AUTOSAR XML (schema 00046)
package /ComponentTypes
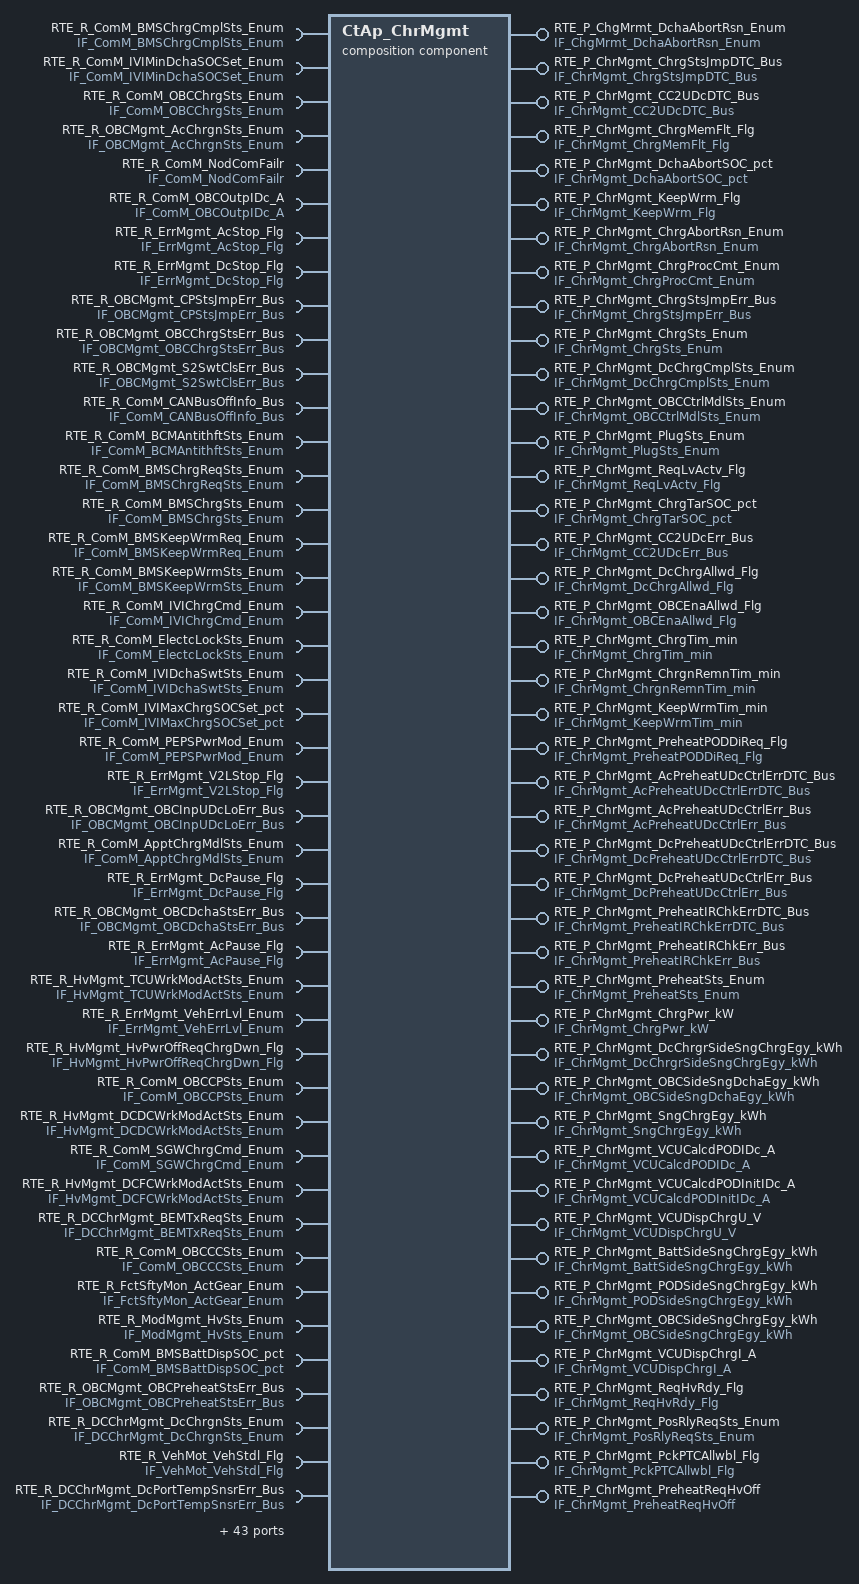
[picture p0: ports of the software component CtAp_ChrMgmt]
  composition sw component type CtAp_ChrMgmt
    4 x require port:
      RTE_R_ComM_BMSChrgCmplSts_Enum: nonqueued-receiver-com-spec{data-element=tec_ComM_BMSChrgCmplSts_Enum, filter=data-filter-type=ALWAYS, init-value=0}, required-interface=IF_ComM_BMSChrgCmplSts_Enum
      RTE_R_ComM_IVIMinDchaSOCSet_Enum: nonqueued-receiver-com-spec{data-element=tec_ComM_IVIMinDchaSOCSet_Enum, filter=data-filter-type=ALWAYS, init-value=0}, required-interface=IF_ComM_IVIMinDchaSOCSet_Enum
      RTE_R_ComM_OBCChrgSts_Enum: nonqueued-receiver-com-spec{data-element=tec_ComM_OBCChrgSts_Enum, filter=data-filter-type=ALWAYS, init-value=0}, required-interface=IF_ComM_OBCChrgSts_Enum
      RTE_R_OBCMgmt_AcChrgnSts_Enum: nonqueued-receiver-com-spec{data-element=tec_OBCMgmt_AcChrgnSts_Enum, filter=data-filter-type=ALWAYS, init-value=0}, required-interface=IF_OBCMgmt_AcChrgnSts_Enum
    40 x provide port:
      RTE_P_ChgMrmt_DchaAbortRsn_Enum: nonqueued-sender-com-spec{data-element=tec_ChrMgmt_DchaAbortRsn_Enum, init-value=0}, provided-interface=IF_ChgMrmt_DchaAbortRsn_Enum
      RTE_P_ChrMgmt_ChrgStsJmpDTC_Bus: nonqueued-sender-com-spec{data-element=tec_ChrMgmt_ChrgStsJmpErrDTC_Bus, init-value=fields=[ChrMgmt_MonStatChrgStsJmpErrDTC:0, ChrMgmt_MonResChrgStsJmpErrDTC:0, ChrMgmt_ErrStatChrgStsJmpErrDTC:0, ChrMgmt_ErrResChrgStsJmpErrDTC:0]}, provided-interface=IF_ChrMgmt_ChrgStsJmpDTC_Bus
      RTE_P_ChrMgmt_CC2UDcDTC_Bus: nonqueued-sender-com-spec{data-element=tec_ChrMgmt_CC2UDcErrDTC_Bus, init-value=fields=[ChrMgmt_MonStatCC2UDcErrDTC:0, ChrMgmt_MonResCC2UDcErrDTC:0, ChrMgmt_ErrStatCC2UDcErrDTC:0, ChrMgmt_ErrResCC2UDcErrDTC:0]}, provided-interface=IF_ChrMgmt_CC2UDcDTC_Bus
      RTE_P_ChrMgmt_ChrgMemFlt_Flg: nonqueued-sender-com-spec{data-element=tec_ChrMgmt_ChrgMemFlt_Flg, init-value=0}, provided-interface=IF_ChrMgmt_ChrgMemFlt_Flg
      RTE_P_ChrMgmt_DchaAbortSOC_pct: nonqueued-sender-com-spec{data-element=tec_ChrMgmt_DchaAbortSOC_pct, init-value=0}, provided-interface=IF_ChrMgmt_DchaAbortSOC_pct
      RTE_P_ChrMgmt_KeepWrm_Flg: nonqueued-sender-com-spec{data-element=tec_ChrMgmt_KeepWrm_Flg, init-value=0}, provided-interface=IF_ChrMgmt_KeepWrm_Flg
      RTE_P_ChrMgmt_ChrgAbortRsn_Enum: nonqueued-sender-com-spec{data-element=tec_ChrMgmt_ChrgAbortRsn_Enum, init-value=0}, provided-interface=IF_ChrMgmt_ChrgAbortRsn_Enum
      RTE_P_ChrMgmt_ChrgProcCmt_Enum: nonqueued-sender-com-spec{data-element=tec_ChrMgmt_ChrgProcCmt_Enum, init-value=0}, provided-interface=IF_ChrMgmt_ChrgProcCmt_Enum
      RTE_P_ChrMgmt_ChrgStsJmpErr_Bus: nonqueued-sender-com-spec{data-element=tec_ChrMgmt_ChrgStsJmpErr_Bus, init-value=fields=[ChrMgmt_MonStatChrgStsJmpErr:0, ChrMgmt_MonResChrgStsJmpErr:0, ChrMgmt_ErrStatChrgStsJmpErr:0, ChrMgmt_ErrResChrgStsJmpErr:0]}, provided-interface=IF_ChrMgmt_ChrgStsJmpErr_Bus
      RTE_P_ChrMgmt_ChrgSts_Enum: nonqueued-sender-com-spec{data-element=tec_ChrMgmt_ChrgSts_Enum, init-value=0}, provided-interface=IF_ChrMgmt_ChrgSts_Enum
      RTE_P_ChrMgmt_DcChrgCmplSts_Enum: nonqueued-sender-com-spec{data-element=tec_ChrMgmt_DcChrgCmplSts_Enum, init-value=0}, provided-interface=IF_ChrMgmt_DcChrgCmplSts_Enum
      RTE_P_ChrMgmt_OBCCtrlMdlSts_Enum: nonqueued-sender-com-spec{data-element=tec_ChrMgmt_OBCCtrlMdlSts_Enum, init-value=0}, provided-interface=IF_ChrMgmt_OBCCtrlMdlSts_Enum
      RTE_P_ChrMgmt_PlugSts_Enum: nonqueued-sender-com-spec{data-element=tec_ChrMgmt_PlugSts_Enum, init-value=0}, provided-interface=IF_ChrMgmt_PlugSts_Enum
      RTE_P_ChrMgmt_ReqLvActv_Flg: nonqueued-sender-com-spec{data-element=tec_ChrMgmt_ReqLvActv_Flg, init-value=0}, provided-interface=IF_ChrMgmt_ReqLvActv_Flg
      RTE_P_ChrMgmt_ChrgTarSOC_pct: nonqueued-sender-com-spec{data-element=tec_ChrMgmt_ChrgTarSOC_pct, init-value=0}, provided-interface=IF_ChrMgmt_ChrgTarSOC_pct
      RTE_P_ChrMgmt_CC2UDcErr_Bus: nonqueued-sender-com-spec{data-element=tec_ChrMgmt_CC2UDcErr_Bus, init-value=fields=[ChrMgmt_MonStatCC2UDcErr:0, ChrMgmt_MonResCC2UDcErr:0, ChrMgmt_ErrStatCC2UDcErr:0, ChrMgmt_ErrResCC2UDcErr:0]}, provided-interface=IF_ChrMgmt_CC2UDcErr_Bus
      RTE_P_ChrMgmt_DcChrgAllwd_Flg: nonqueued-sender-com-spec{data-element=tec_ChrMgmt_DcChrgAllwd_Flg, init-value=0}, provided-interface=IF_ChrMgmt_DcChrgAllwd_Flg
      RTE_P_ChrMgmt_OBCEnaAllwd_Flg: nonqueued-sender-com-spec{data-element=tec_ChrMgmt_OBCEnaAllwd_Flg, init-value=0}, provided-interface=IF_ChrMgmt_OBCEnaAllwd_Flg
      RTE_P_ChrMgmt_ChrgTim_min: nonqueued-sender-com-spec{data-element=tec_ChrMgmt_ChrgTim_min, init-value=0}, provided-interface=IF_ChrMgmt_ChrgTim_min
      RTE_P_ChrMgmt_ChrgnRemnTim_min: nonqueued-sender-com-spec{data-element=tec_ChrgMgmt_ChrgnRemnTim_min, init-value=0}, provided-interface=IF_ChrMgmt_ChrgnRemnTim_min
      RTE_P_ChrMgmt_KeepWrmTim_min: nonqueued-sender-com-spec{data-element=tec_ChrMgmt_KeepWrmTim_min, init-value=0}, provided-interface=IF_ChrMgmt_KeepWrmTim_min
      RTE_P_ChrMgmt_PreheatPODDiReq_Flg: nonqueued-sender-com-spec{data-element=tec_ChrMgmt_PreheatPODDiReq_Flg, init-value=0}, provided-interface=IF_ChrMgmt_PreheatPODDiReq_Flg
      RTE_P_ChrMgmt_AcPreheatUDcCtrlErrDTC_Bus: nonqueued-sender-com-spec{data-element=tec_ChrMgmt_AcPreheatUDcCtrlErrDTC_Bus, init-value=fields=[ChrMgmt_MonStatAcPreheatUDcCtrlErrDTC:0, ChrMgmt_MonResAcPreheatUDcCtrlErrDTC:0, ChrMgmt_ErrStatAcPreheatUDcCtrlErrDTC:0, ChrMgmt_ErrResAcPreheatUDcCtrlErrDTC:0]}, provided-interface=IF_ChrMgmt_AcPreheatUDcCtrlErrDTC_Bus
      RTE_P_ChrMgmt_AcPreheatUDcCtrlErr_Bus: nonqueued-sender-com-spec{data-element=tec_ChrMgmt_AcPreheatUDcCtrlErr_Bus, init-value=fields=[ChrMgmt_MonStatAcPreheatUDcCtrlErr:0, ChrMgmt_MonResAcPreheatUDcCtrlErr:0, ChrMgmt_ErrStatAcPreheatUDcCtrlErr:0, ChrMgmt_ErrResAcPreheatUDcCtrlErr:0]}, provided-interface=IF_ChrMgmt_AcPreheatUDcCtrlErr_Bus
      RTE_P_ChrMgmt_DcPreheatUDcCtrlErrDTC_Bus: nonqueued-sender-com-spec{data-element=tec_ChrMgmt_DcPreheatUDcCtrlErrDTC_Bus, init-value=fields=[ChrMgmt_MonStatDcPreheatUDcCtrlErrDTC:0, ChrMgmt_MonResDcPreheatUDcCtrlErrDTC:0, ChrMgmt_ErrStatDcPreheatUDcCtrlErrDTC:0, ChrMgmt_ErrResDcPreheatUDcCtrlErrDTC:0]}, provided-interface=IF_ChrMgmt_DcPreheatUDcCtrlErrDTC_Bus
      RTE_P_ChrMgmt_DcPreheatUDcCtrlErr_Bus: nonqueued-sender-com-spec{data-element=tec_ChrMgmt_DcPreheatUDcCtrlErr_Bus, init-value=fields=[ChrMgmt_MonStatDcPreheatUDcCtrlErr:0, ChrMgmt_MonResDcPreheatUDcCtrlErr:0, ChrMgmt_ErrStatDcPreheatUDcCtrlErr:0, ChrMgmt_ErrResDcPreheatUDcCtrlErr:0]}, provided-interface=IF_ChrMgmt_DcPreheatUDcCtrlErr_Bus
      RTE_P_ChrMgmt_PreheatIRChkErrDTC_Bus: nonqueued-sender-com-spec{data-element=tec_ChrMgmt_PreheatIRChkErrDTC_Bus, init-value=fields=[ChrMgmt_MonStatPreheatIRChkErrDTC:0, ChrMgmt_MonResPreheatIRChkErrDTC:0, ChrMgmt_ErrStatPreheatIRChkErrDTC:0, ChrMgmt_ErrResPreheatIRChkErrDTC:0]}, provided-interface=IF_ChrMgmt_PreheatIRChkErrDTC_Bus
      RTE_P_ChrMgmt_PreheatIRChkErr_Bus: nonqueued-sender-com-spec{data-element=tec_ChrMgmt_PreheatIRChkErr_Bus, init-value=fields=[ChrMgmt_MonStatPreheatIRChkErr:0, ChrMgmt_MonResPreheatIRChkErr:0, ChrMgmt_ErrStatPreheatIRChkErr:0, ChrMgmt_ErrResPreheatIRChkErr:0]}, provided-interface=IF_ChrMgmt_PreheatIRChkErr_Bus
      RTE_P_ChrMgmt_PreheatSts_Enum: nonqueued-sender-com-spec{data-element=tec_ChrMgmt_PreheatSts_Enum, init-value=0}, provided-interface=IF_ChrMgmt_PreheatSts_Enum
      RTE_P_ChrMgmt_ChrgPwr_kW: nonqueued-sender-com-spec{data-element=tec_ChrMgmt_VCUDispChrgPwr_kW, init-value=0}, provided-interface=IF_ChrMgmt_ChrgPwr_kW
      RTE_P_ChrMgmt_DcChrgrSideSngChrgEgy_kWh: nonqueued-sender-com-spec{data-element=tec_ChrMgmt_DcChrgrSideSngChrgEgy_kWh, init-value=0}, provided-interface=IF_ChrMgmt_DcChrgrSideSngChrgEgy_kWh
      RTE_P_ChrMgmt_OBCSideSngDchaEgy_kWh: nonqueued-sender-com-spec{data-element=tec_ChrMgmt_OBCSideSngDchaEgy_kWh, init-value=0}, provided-interface=IF_ChrMgmt_OBCSideSngDchaEgy_kWh
      RTE_P_ChrMgmt_SngChrgEgy_kWh: nonqueued-sender-com-spec{data-element=tec_ChrMgmt_SngChrgEgy_kWh, init-value=0}, provided-interface=IF_ChrMgmt_SngChrgEgy_kWh
      RTE_P_ChrMgmt_VCUCalcdPODIDc_A: nonqueued-sender-com-spec{data-element=tec_ChrMgmt_VCUCalcdPODIDc_A, init-value=0}, provided-interface=IF_ChrMgmt_VCUCalcdPODIDc_A
      RTE_P_ChrMgmt_VCUCalcdPODInitIDc_A: nonqueued-sender-com-spec{data-element=tec_ChrMgmt_VCUCalcdPODInitIDc_A, init-value=0}, provided-interface=IF_ChrMgmt_VCUCalcdPODInitIDc_A
      RTE_P_ChrMgmt_VCUDispChrgU_V: nonqueued-sender-com-spec{data-element=tec_ChrMgmt_VCUDispChrgU_V, init-value=0}, provided-interface=IF_ChrMgmt_VCUDispChrgU_V
      RTE_P_ChrMgmt_BattSideSngChrgEgy_kWh: nonqueued-sender-com-spec{data-element=tec_ChrMgmt_BattSideSngChrgEgy_kWh, init-value=0}, provided-interface=IF_ChrMgmt_BattSideSngChrgEgy_kWh
      RTE_P_ChrMgmt_PODSideSngChrgEgy_kWh: nonqueued-sender-com-spec{data-element=tec_ChrMgmt_PODSideSngChrgEgy_kWh, init-value=0}, provided-interface=IF_ChrMgmt_PODSideSngChrgEgy_kWh
      RTE_P_ChrMgmt_OBCSideSngChrgEgy_kWh: nonqueued-sender-com-spec{data-element=tec_ChrMgmt_OBCSideSngChrgEgy_kWh, init-value=0}, provided-interface=IF_ChrMgmt_OBCSideSngChrgEgy_kWh
      RTE_P_ChrMgmt_VCUDispChrgI_A: nonqueued-sender-com-spec{data-element=tec_ChrMgmt_VCUDispChrgI_A, init-value=0}, provided-interface=IF_ChrMgmt_VCUDispChrgI_A
    44 x require port:
      RTE_R_ComM_NodComFailr: required-interface=IF_ComM_NodComFailr
        required-com-specs:
          data-element=tec_ComM_ACUNodComFailr_Flg, filter=data-filter-type=ALWAYS, init-value=0
          data-element=tec_ComM_SGWNodComFailr_Flg, filter=data-filter-type=ALWAYS, init-value=0
          data-element=tec_ComM_CGWNodComFailr_Flg, filter=data-filter-type=ALWAYS, init-value=0
          data-element=tec_ComM_TCUNodComFailr_Flg, filter=data-filter-type=ALWAYS, init-value=0
          data-element=tec_ComM_BCMNodComFailr_Flg, filter=data-filter-type=ALWAYS, init-value=0
          data-element=tec_ComM_PRNDNodComFailr_Flg, filter=data-filter-type=ALWAYS, init-value=0
          data-element=tec_ComM_IVINodComFailr_Flg, filter=data-filter-type=ALWAYS, init-value=0
          data-element=tec_ComM_DCDCNodComFailr_Flg, filter=data-filter-type=ALWAYS, init-value=0
          data-element=tec_ComM_OBCNodComFailr_Flg, filter=data-filter-type=ALWAYS, init-value=0
          data-element=tec_ComM_CHIBSNodComFailr_Flg, filter=data-filter-type=ALWAYS, init-value=0
          data-element=tec_ComM_MCUNodComFailr_Flg, filter=data-filter-type=ALWAYS, init-value=0
          data-element=tec_ComM_EVCOMNodComFailr_Flg, filter=data-filter-type=ALWAYS, init-value=0
          data-element=tec_ComM_EPTIBSNodComFailr_Flg, filter=data-filter-type=ALWAYS, init-value=0
          data-element=tec_ComM_DCMNodComFailr_Flg, filter=data-filter-type=ALWAYS, init-value=0
          data-element=tec_ComM_BMSNodComFailr_Flg, filter=data-filter-type=ALWAYS, init-value=0
          data-element=tec_ComM_APTCNodComFailr_Flg, filter=data-filter-type=ALWAYS, init-value=0
          data-element=tec_ComM_ADCUNodComFailr_Flg, filter=data-filter-type=ALWAYS, init-value=0
          data-element=tec_ComM_DCMRRNodComFailr_Flg, filter=data-filter-type=ALWAYS, init-value=0
          data-element=tec_ComM_DCMRLNodComFailr_Flg, filter=data-filter-type=ALWAYS, init-value=0
          data-element=tec_ComM_DCMFRNodComFailr_Flg, filter=data-filter-type=ALWAYS, init-value=0
          data-element=tec_ComM_DCMFLNodComFailr_Flg, filter=data-filter-type=ALWAYS, init-value=0
          data-element=tec_ComM_SGWCHNodComFailr_Flg, filter=data-filter-type=ALWAYS, init-value=0
      RTE_R_ComM_OBCOutpIDc_A: nonqueued-receiver-com-spec{data-element=tec_ComM_OBCOutpIDc_A, filter=data-filter-type=ALWAYS, init-value=0}, required-interface=IF_ComM_OBCOutpIDc_A
      RTE_R_ErrMgmt_AcStop_Flg: nonqueued-receiver-com-spec{data-element=tec_ErrMgmt_AcStop_Flg, filter=data-filter-type=ALWAYS, init-value=0}, required-interface=IF_ErrMgmt_AcStop_Flg
      RTE_R_ErrMgmt_DcStop_Flg: nonqueued-receiver-com-spec{data-element=tec_ErrMgmt_DcStop_Flg, filter=data-filter-type=ALWAYS, init-value=0}, required-interface=IF_ErrMgmt_DcStop_Flg
      RTE_R_OBCMgmt_CPStsJmpErr_Bus: nonqueued-receiver-com-spec{data-element=tec_OBCMgmt_CPStsJmpErr_Bus, filter=data-filter-type=ALWAYS, init-value=fields=[OBCMgmt_MonStatCPStsJmpErr:0, OBCMgmt_MonResCPStsJmpErr:0, OBCMgmt_ErrStatCPStsJmpErr:0, OBCMgmt_ErrResCPStsJmpErr:0]}, required-interface=IF_OBCMgmt_CPStsJmpErr_Bus
      RTE_R_OBCMgmt_OBCChrgStsErr_Bus: nonqueued-receiver-com-spec{data-element=tec_OBCMgmt_OBCChrgStsErr_Bus, filter=data-filter-type=ALWAYS, init-value=fields=[OBCMgmt_MonStatOBCChrgStsErr:0, OBCMgmt_MonResOBCChrgStsErr:0, OBCMgmt_ErrStatOBCChrgStsErr:0, OBCMgmt_ErrResOBCChrgStsErr:0]}, required-interface=IF_OBCMgmt_OBCChrgStsErr_Bus
      RTE_R_OBCMgmt_S2SwtClsErr_Bus: nonqueued-receiver-com-spec{data-element=tec_OBCMgmt_S2SwtClsErr_Bus, filter=data-filter-type=ALWAYS, init-value=fields=[OBCMgmt_MonStatS2SwtClsErr:0, OBCMgmt_MonResS2SwtClsErr:0, OBCMgmt_ErrStatS2SwtClsErr:0, OBCMgmt_ErrResS2SwtClsErr:0]}, required-interface=IF_OBCMgmt_S2SwtClsErr_Bus
      RTE_R_ComM_CANBusOffInfo_Bus: required-interface=IF_ComM_CANBusOffInfo_Bus
        required-com-specs:
          data-element=tec_ComM_EPTCANBusOffInfo_Bus, filter=data-filter-type=ALWAYS, init-value=fields=[ComM_MonStatEPTCANBusOffInfo:0, ComM_MonResEPTCANBusOffInfo:0, ComM_ErrStatEPTCANBusOffInfo:0, ComM_ErrResEPTCANBusOffInfo:0]
          data-element=tec_ComM_CHCANBusOffInfo_Bus, filter=data-filter-type=ALWAYS, init-value=fields=[ComM_MonStatCHCANBusOffInfo:0, ComM_MonResCHCANBusOffInfo:0, ComM_ErrStatCHCANBusOffInfo:0, ComM_ErrResCHCANBusOffInfo:0]
          data-element=tec_ComM_EPTCANBusOffDTCInfo_Bus, filter=data-filter-type=ALWAYS, init-value=fields=[ComM_MonStatEPTCANBusOffDTCInfo:0, ComM_MonResEPTCANBusOffDTCInfo:0, ComM_ErrStatEPTCANBusOffDTCInfo:0, ComM_ErrResEPTCANBusOffDTCInfo:0]
          data-element=tec_ComM_CHCANBusOffDTCInfo_Bus, filter=data-filter-type=ALWAYS, init-value=fields=[ComM_MonStatCHCANBusOffDTCInfo:0, ComM_MonResCHCANBusOffDTCInfo:0, ComM_ErrStatCHCANBusOffDTCInfo:0, ComM_ErrResCHCANBusOffDTCInfo:0]
      RTE_R_ComM_BCMAntithftSts_Enum: nonqueued-receiver-com-spec{data-element=tec_ComM_BCMAntithftSts_Enum, filter=data-filter-type=ALWAYS, init-value=0}, required-interface=IF_ComM_BCMAntithftSts_Enum
      RTE_R_ComM_BMSChrgReqSts_Enum: nonqueued-receiver-com-spec{data-element=tec_ComM_BMSChrgReqSts_Enum, filter=data-filter-type=ALWAYS, init-value=0}, required-interface=IF_ComM_BMSChrgReqSts_Enum
      RTE_R_ComM_BMSChrgSts_Enum: nonqueued-receiver-com-spec{data-element=tec_ComM_BMSChrgSts_Enum, filter=data-filter-type=ALWAYS, init-value=0}, required-interface=IF_ComM_BMSChrgSts_Enum
      RTE_R_ComM_BMSKeepWrmReq_Enum: nonqueued-receiver-com-spec{data-element=tec_ComM_BMSKeepWrmReq_Enum, filter=data-filter-type=ALWAYS, init-value=0}, required-interface=IF_ComM_BMSKeepWrmReq_Enum
      RTE_R_ComM_BMSKeepWrmSts_Enum: nonqueued-receiver-com-spec{data-element=tec_ComM_BMSKeepWrmSts_Enum, filter=data-filter-type=ALWAYS, init-value=0}, required-interface=IF_ComM_BMSKeepWrmSts_Enum
      RTE_R_ComM_IVIChrgCmd_Enum: nonqueued-receiver-com-spec{data-element=tec_ComM_IVIChrgCmd_Enum, filter=data-filter-type=ALWAYS, init-value=0}, required-interface=IF_ComM_IVIChrgCmd_Enum
      RTE_R_ComM_ElectcLockSts_Enum: nonqueued-receiver-com-spec{data-element=tec_ComM_ElectcLockSts_Enum, filter=data-filter-type=ALWAYS, init-value=0}, required-interface=IF_ComM_ElectcLockSts_Enum
      RTE_R_ComM_IVIDchaSwtSts_Enum: nonqueued-receiver-com-spec{data-element=tec_ComM_IVIDchaSwtSts_Enum, filter=data-filter-type=ALWAYS, init-value=0}, required-interface=IF_ComM_IVIDchaSwtSts_Enum
      RTE_R_ComM_IVIMaxChrgSOCSet_pct: nonqueued-receiver-com-spec{data-element=tec_ComM_IVIMaxChrgSOCSet_pct, filter=data-filter-type=ALWAYS, init-value=0}, required-interface=IF_ComM_IVIMaxChrgSOCSet_pct
      RTE_R_ComM_PEPSPwrMod_Enum: nonqueued-receiver-com-spec{data-element=tec_ComM_PEPSPwrMod_Enum, filter=data-filter-type=ALWAYS, init-value=0}, required-interface=IF_ComM_PEPSPwrMod_Enum
      RTE_R_ErrMgmt_V2LStop_Flg: nonqueued-receiver-com-spec{data-element=tec_ErrMgmt_V2LStop_Flg, filter=data-filter-type=ALWAYS, init-value=0}, required-interface=IF_ErrMgmt_V2LStop_Flg
      RTE_R_OBCMgmt_OBCInpUDcLoErr_Bus: nonqueued-receiver-com-spec{data-element=tec_OBCMgmt_OBCInpUDcLoErr_Bus, filter=data-filter-type=ALWAYS, init-value=fields=[OBCMgmt_MonStatOBCInpUDcLoErr:0, OBCMgmt_MonResOBCInpUDcLoErr:0, OBCMgmt_ErrStatOBCInpUDcLoErr:0, OBCMgmt_ErrResOBCInpUDcLoErr:0]}, required-interface=IF_OBCMgmt_OBCInpUDcLoErr_Bus
      RTE_R_ComM_ApptChrgMdlSts_Enum: nonqueued-receiver-com-spec{data-element=tec_ComM_ApptChrgMdlSts_Enum, filter=data-filter-type=ALWAYS, init-value=0}, required-interface=IF_ComM_ApptChrgMdlSts_Enum
      RTE_R_ErrMgmt_DcPause_Flg: nonqueued-receiver-com-spec{data-element=tec_ErrMgmt_DcPause_Flg, filter=data-filter-type=ALWAYS, init-value=0}, required-interface=IF_ErrMgmt_DcPause_Flg
      RTE_R_OBCMgmt_OBCDchaStsErr_Bus: nonqueued-receiver-com-spec{data-element=tec_OBCMgmt_OBCDchaStsErr_Bus, filter=data-filter-type=ALWAYS, init-value=fields=[OBCMgmt_MonStatOBCDchaStsErr:0, OBCMgmt_MonResOBCDchaStsErr:0, OBCMgmt_ErrStatOBCDchaStsErr:0, OBCMgmt_ErrResOBCDchaStsErr:0]}, required-interface=IF_OBCMgmt_OBCDchaStsErr_Bus
      RTE_R_ErrMgmt_AcPause_Flg: nonqueued-receiver-com-spec{data-element=tec_ErrMgmt_AcPause_Flg, filter=data-filter-type=ALWAYS, init-value=0}, required-interface=IF_ErrMgmt_AcPause_Flg
      RTE_R_HvMgmt_TCUWrkModActSts_Enum: nonqueued-receiver-com-spec{data-element=tec_HvMgmt_TCUWrkModActSts_Enum, filter=data-filter-type=ALWAYS, init-value=0}, required-interface=IF_HvMgmt_TCUWrkModActSts_Enum
      RTE_R_ErrMgmt_VehErrLvl_Enum: nonqueued-receiver-com-spec{data-element=tec_ErrMgmt_VehErrLvl_Enum, filter=data-filter-type=ALWAYS, init-value=0}, required-interface=IF_ErrMgmt_VehErrLvl_Enum
      RTE_R_HvMgmt_HvPwrOffReqChrgDwn_Flg: nonqueued-receiver-com-spec{data-element=tec_HvMgmt_HvPwrOffReqChrgDwn_Flg, filter=data-filter-type=ALWAYS, init-value=0}, required-interface=IF_HvMgmt_HvPwrOffReqChrgDwn_Flg
      RTE_R_ComM_OBCCPSts_Enum: nonqueued-receiver-com-spec{data-element=tec_ComM_OBCCPSts_Enum, filter=data-filter-type=ALWAYS, init-value=0}, required-interface=IF_ComM_OBCCPSts_Enum
      RTE_R_HvMgmt_DCDCWrkModActSts_Enum: nonqueued-receiver-com-spec{data-element=tec_HvMgmt_DCDCWrkModActSts_Enum, filter=data-filter-type=ALWAYS, init-value=0}, required-interface=IF_HvMgmt_DCDCWrkModActSts_Enum
      RTE_R_ComM_SGWChrgCmd_Enum: nonqueued-receiver-com-spec{data-element=tec_ComM_SGWChrgCmd_Enum, filter=data-filter-type=ALWAYS, init-value=0}, required-interface=IF_ComM_SGWChrgCmd_Enum
      RTE_R_HvMgmt_DCFCWrkModActSts_Enum: nonqueued-receiver-com-spec{data-element=tec_HvMgmt_DCFCWrkModActSts_Enum, filter=data-filter-type=ALWAYS, init-value=0}, required-interface=IF_HvMgmt_DCFCWrkModActSts_Enum
      RTE_R_DCChrMgmt_BEMTxReqSts_Enum: nonqueued-receiver-com-spec{data-element=tec_DCChrMgmt_BEMTxReqSts_Enum, filter=data-filter-type=ALWAYS, init-value=0}, required-interface=IF_DCChrMgmt_BEMTxReqSts_Enum
      RTE_R_ComM_OBCCCSts_Enum: nonqueued-receiver-com-spec{data-element=tec_ComM_OBCCCSts_Enum, filter=data-filter-type=ALWAYS, init-value=0}, required-interface=IF_ComM_OBCCCSts_Enum
      RTE_R_FctSftyMon_ActGear_Enum: nonqueued-receiver-com-spec{data-element=tec_FctSftyMon_ActGear_Enum, filter=data-filter-type=ALWAYS, init-value=0}, required-interface=IF_FctSftyMon_ActGear_Enum
      RTE_R_ModMgmt_HvSts_Enum: nonqueued-receiver-com-spec{data-element=tec_ModMgmt_HvSts_Enum, filter=data-filter-type=ALWAYS, init-value=0}, required-interface=IF_ModMgmt_HvSts_Enum
      RTE_R_ComM_BMSBattDispSOC_pct: nonqueued-receiver-com-spec{data-element=tec_ComM_BMSBattDispSOC_pct, filter=data-filter-type=ALWAYS, init-value=0}, required-interface=IF_ComM_BMSBattDispSOC_pct
      RTE_R_OBCMgmt_OBCPreheatStsErr_Bus: nonqueued-receiver-com-spec{data-element=tec_OBCMgmt_OBCPreheatStsErr_Bus, filter=data-filter-type=ALWAYS, init-value=fields=[OBCMgmt_MonStatOBCPreheatStsErr:0, OBCMgmt_MonResOBCPreheatStsErr:0, OBCMgmt_ErrStatOBCPreheatStsErr:0, OBCMgmt_ErrResOBCPreheatStsErr:0]}, required-interface=IF_OBCMgmt_OBCPreheatStsErr_Bus
      RTE_R_DCChrMgmt_DcChrgnSts_Enum: nonqueued-receiver-com-spec{data-element=tec_DCChrMgmt_DcChrgnSts_Enum, filter=data-filter-type=ALWAYS, init-value=0}, required-interface=IF_DCChrMgmt_DcChrgnSts_Enum
      RTE_R_VehMot_VehStdl_Flg: nonqueued-receiver-com-spec{data-element=tec_VehMot_VehStdl_Flg, filter=data-filter-type=ALWAYS, init-value=0}, required-interface=IF_VehMot_VehStdl_Flg
      RTE_R_DCChrMgmt_DcPortTempSnsrErr_Bus: nonqueued-receiver-com-spec{data-element=tec_DCChrMgmt_DcPortTempSnsrErr_Bus, filter=data-filter-type=ALWAYS, init-value=fields=[DCChrMgmt_MonStatDcPortTempSnsrErr:0, DCChrMgmt_MonResDcPortTempSnsrErr:0, DCChrMgmt_ErrStatDcPortTempSnsrErr:0, DCChrMgmt_ErrResDcPortTempSnsrErr:0]}, required-interface=IF_DCChrMgmt_DcPortTempSnsrErr_Bus
      RTE_R_DCChrMgmt_IRMeasEnaErr_Bus: nonqueued-receiver-com-spec{data-element=tec_DCChrMgmt_IRMeasEnaErr_Bus, filter=data-filter-type=ALWAYS, init-value=fields=[DCChrMgmt_MonStatIRMeasEnaErr:0, DCChrMgmt_MonResIRMeasEnaErr:0, DCChrMgmt_ErrStatIRMeasEnaErr:0, DCChrMgmt_ErrResIRMeasEnaErr:0]}, required-interface=IF_DCChrMgmt_IRMeasEnaErr_Bus
      RTE_R_OBCMgmt_OBCDiErr_Bus: nonqueued-receiver-com-spec{data-element=tec_OBCMgmt_OBCDiErr_Bus, filter=data-filter-type=ALWAYS, init-value=fields=[OBCMgmt_MonStatOBCDiErr:0, OBCMgmt_MonResOBCDiErr:0, OBCMgmt_ErrStatOBCDiErr:0, OBCMgmt_ErrResOBCDiErr:0]}, required-interface=IF_OBCMgmt_OBCDiErr_Bus
      RTE_R_LvMgmt_BSBattUDcNorm_Flg: nonqueued-receiver-com-spec{data-element=tec_LvMgmt_BSBattUDcNorm_Flg, filter=data-filter-type=ALWAYS, init-value=0}, required-interface=IF_LvMgmt_BSBattUDcNorm_Flg
      RTE_R_DCChrMgmt_DcPortTempErrLvl2_Bus: nonqueued-receiver-com-spec{data-element=tec_DCChrMgmt_DcPortTempErrLvl2_Bus, filter=data-filter-type=ALWAYS, init-value=fields=[DCChrMgmt_MonStatDcPortTempErrLvl2:0, DCChrMgmt_MonResDcPortTempErrLvl2:0, DCChrMgmt_ErrStatDcPortTempErrLvl2:0, DCChrMgmt_ErrResDcPortTempErrLvl2:0]}, required-interface=IF_DCChrMgmt_DcPortTempErrLvl2_Bus
    provide port RTE_P_ChrMgmt_ReqHvRdy_Flg: nonqueued-sender-com-spec{data-element=tec_ChrMgmt_ReqHvRdy_Flg, init-value=0}, provided-interface=IF_ChrMgmt_ReqHvRdy_Flg
    28 x require port:
      RTE_R_HvMgmt_BMSPosRlyActSts_Enum: nonqueued-receiver-com-spec{data-element=tec_HvMgmt_BMSPosRlyActSts_Enum, filter=data-filter-type=ALWAYS, init-value=0}, required-interface=IF_HvMgmt_BMSPosRlyActSts_Enum
      RTE_R_IOAbs_CC2SigUDc_mV: nonqueued-receiver-com-spec{data-element=tec_IOAbs_CC2SigUDc_mV, filter=data-filter-type=ALWAYS, init-value=0}, required-interface=IF_IOAbs_CC2SigUDc_mV
      RTE_R_DCChrMgmt_IRMeasDiErr_Bus: nonqueued-receiver-com-spec{data-element=tec_DCChrMgmt_IRMeasDiErr_Bus, filter=data-filter-type=ALWAYS, init-value=fields=[DCChrMgmt_MonStatIRMeasDiErr:0, DCChrMgmt_MonResIRMeasDiErr:0, DCChrMgmt_ErrStatIRMeasDiErr:0, DCChrMgmt_ErrResIRMeasDiErr:0]}, required-interface=IF_DCChrMgmt_IRMeasDiErr_Bus
      RTE_R_ComM_BMSRemnChrgTim_min: nonqueued-receiver-com-spec{data-element=tec_ComM_BMSRemnChrgTim_min, filter=data-filter-type=ALWAYS, init-value=0}, required-interface=IF_ComM_BMSRemnChrgTim_min
      RTE_R_ComM_BattMinTemp_C: nonqueued-receiver-com-spec{data-element=tec_ComM_BMSBattMinTemp_C, filter=data-filter-type=ALWAYS, init-value=0}, required-interface=IF_ComM_BattMinTemp_C
      RTE_R_ComM_CMLMaxOutpIDc_A: nonqueued-receiver-com-spec{data-element=tec_ComM_CMLMaxOutpIDc_A, filter=data-filter-type=ALWAYS, init-value=0}, required-interface=IF_ComM_CMLMaxOutpIDc_A
      RTE_R_ChrMgmt_ChrgSts_Enum: nonqueued-receiver-com-spec{data-element=tec_ChrMgmt_ChrgSts_Enum, filter=data-filter-type=ALWAYS, init-value=0}, required-interface=IF_ChrMgmt_ChrgSts_Enum
      RTE_R_ChrMgmt_ChrgTarSOC_pct: nonqueued-receiver-com-spec{data-element=tec_ChrMgmt_ChrgTarSOC_pct, filter=data-filter-type=ALWAYS, init-value=0}, required-interface=IF_ChrMgmt_ChrgTarSOC_pct
      RTE_R_ComM_BMSBattRateCp_Ah: nonqueued-receiver-com-spec{data-element=tec_ComM_BMSBattRateCp_Ah, filter=data-filter-type=ALWAYS, init-value=0}, required-interface=IF_ComM_BMSBattRateCp_Ah
      RTE_R_DCChrMgmt_DcChrgnMod_Enum: nonqueued-receiver-com-spec{data-element=tec_DCChrMgmt_DcChrgnMod_Enum, filter=data-filter-type=ALWAYS, init-value=0}, required-interface=IF_DCChrMgmt_DcChrgnMod_Enum
      RTE_R_ComM_BattMaxTemp_C: nonqueued-receiver-com-spec{data-element=tec_ComM_BMSBattMaxTemp_C, filter=data-filter-type=ALWAYS, init-value=0}, required-interface=IF_ComM_BattMaxTemp_C
      RTE_R_OBCMgmt_OBCOutpCpbyIDc_A: nonqueued-receiver-com-spec{data-element=tec_OBCMgmt_OBCOutpCpbyIDc_A, filter=data-filter-type=ALWAYS, init-value=0}, required-interface=IF_OBCMgmt_OBCOutpCpbyIDc_A
      RTE_R_ComM_CCSOutpIDc_A: nonqueued-receiver-com-spec{data-element=tec_ComM_CCSOutpIDc_A, filter=data-filter-type=ALWAYS, init-value=0}, required-interface=IF_ComM_CCSOutpIDc_A
      RTE_R_ComM_BMSBattIDc_A: nonqueued-receiver-com-spec{data-element=tec_ComM_BMSBattIDc_A, filter=data-filter-type=ALWAYS, init-value=0}, required-interface=IF_ComM_BMSBattIDc_A
      RTE_R_ComM_BMSBattLnkUDc_V: nonqueued-receiver-com-spec{data-element=tec_ComM_BMSBattLnkUDc_V, filter=data-filter-type=ALWAYS, init-value=0}, required-interface=IF_ComM_BMSBattLnkUDc_V
      RTE_R_EgyMgmt_ACSysPwrCnsCalcn_Kw: nonqueued-receiver-com-spec{data-element=tec_EgyMgmt_ACSysPwrCnsCalcn_Kw, filter=data-filter-type=ALWAYS, init-value=0}, required-interface=IF_EgyMgmt_ACSysPwrCnsCalcn_Kw
      RTE_R_EgyMgmt_PackPTCPwrCnsCalcn_Kw: nonqueued-receiver-com-spec{data-element=tec_EgyMgmt_PackPTCPwrCnsCalcn_Kw, filter=data-filter-type=ALWAYS, init-value=0}, required-interface=IF_EgyMgmt_PackPTCPwrCnsCalcn_Kw
      RTE_R_ComM_PODDCFCUDc_V: nonqueued-receiver-com-spec{data-element=tec_ComM_PODDCFCUDc_V, filter=data-filter-type=ALWAYS, init-value=0}, required-interface=IF_ComM_PODDCFCUDc_V
      RTE_R_EgyMgmt_DCDCPwrCnsCalcn_Kw: nonqueued-receiver-com-spec{data-element=tec_EgyMgmt_DCDCPwrCnsCalcn_Kw, filter=data-filter-type=ALWAYS, init-value=0}, required-interface=IF_EgyMgmt_DCDCPwrCnsCalcn_Kw
      RTE_R_ComM_OBCOutpUDc_V: nonqueued-receiver-com-spec{data-element=tec_ComM_OBCOutpUDc_V, filter=data-filter-type=ALWAYS, init-value=0}, required-interface=IF_ComM_OBCOutpUDc_V
      RTE_R_ComM_OBCInpIAc_A: nonqueued-receiver-com-spec{data-element=tec_ComM_OBCInpIAc_A, filter=data-filter-type=ALWAYS, init-value=0}, required-interface=IF_ComM_OBCInpIAc_A
      RTE_R_ComM_CCSOutpUDc_V: nonqueued-receiver-com-spec{data-element=tec_ComM_CCSOutpUDc_V, filter=data-filter-type=ALWAYS, init-value=0}, required-interface=IF_ComM_CCSOutpUDc_V
      RTE_R_ComM_BMSBattUDc_V: nonqueued-receiver-com-spec{data-element=tec_ComM_BMSBattUDc_V, filter=data-filter-type=ALWAYS, init-value=0}, required-interface=IF_ComM_BMSBattUDc_V
      RTE_R_ComM_OBCInpUAc_V: nonqueued-receiver-com-spec{data-element=tec_ComM_OBCInpUAc_V, filter=data-filter-type=ALWAYS, init-value=0}, required-interface=IF_ComM_OBCInpUAc_V
      RTE_R_ComM_AcChrgPha_Enum: nonqueued-receiver-com-spec{data-element=tec_ComM_AcChrgPha_Enum, filter=data-filter-type=ALWAYS, init-value=0}, required-interface=IF_ComM_AcChrgPha_Enum
      RTE_R_ComM_BMSBattPckUDc_V: nonqueued-receiver-com-spec{data-element=tec_ComM_BMSBattPckUDc_V, filter=data-filter-type=ALWAYS, init-value=0}, required-interface=IF_ComM_BMSBattPckUDc_V
      RTE_R_ComM_SysIRVal_kOhm: nonqueued-receiver-com-spec{data-element=tec_ComM_SysIRVal_kOhm, filter=data-filter-type=ALWAYS, init-value=0}, required-interface=IF_ComM_SysIRVal_kOhm
      RTE_R_ComM_PODDcPosRlySts_Enum: nonqueued-receiver-com-spec{data-element=tec_ComM_PODDcPosRlySts_Enum, filter=data-filter-type=ALWAYS, init-value=0}, required-interface=IF_ComM_PODDcPosRlySts_Enum
    provide/require port RTE_RP_ChrgStatInfo:
      nv-provide-com-spec{ram-block-init-value=fields=[ChrMgmt_ChrgTarSOC_pct:0, ChrMgmt_ChrgMemFlt_Flg:0, ChrMgmt_DchaAbortSOC_pct:0, ChrMgmt_FillAddress:0], rom-block-init-value=fields=[ChrMgmt_ChrgTarSOC_pct:0, ChrMgmt_ChrgMemFlt_Flg:0, ChrMgmt_DchaAbortSOC_pct:0, ChrMgmt_FillAddress:0], variable=tec_ChrgStatInfo}
      nv-require-com-spec{init-value=fields=[ChrMgmt_ChrgTarSOC_pct:0, ChrMgmt_ChrgMemFlt_Flg:0, ChrMgmt_DchaAbortSOC_pct:0, ChrMgmt_FillAddress:0], variable=tec_ChrgStatInfo}
      provided-required-interface=IF_ChrgStatInfo
    provide/require port RTE_RP_ChrgEgyCalInfo:
      nv-provide-com-spec{ram-block-init-value=fields=[ChrMgmt_OBCSideTotDchaEgy_Wh:0, ChrMgmt_PODSideTotChrgEgy_Wh:0, ChrMgmt_BattSideTotChrgEgy_Wh:0, ChrMgmt_DCChrgrSideTotChrgEgy_Wh:0, ChrMgmt_OBCSideTotChrgEgy_Wh:0, ChrMgmt_BattChrgCnt_Tms:0], rom-block-init-value=fields=[ChrMgmt_OBCSideTotDchaEgy_Wh:0, ChrMgmt_PODSideTotChrgEgy_Wh:0, ChrMgmt_BattSideTotChrgEgy_Wh:0, ChrMgmt_DCChrgrSideTotChrgEgy_Wh:0, ChrMgmt_OBCSideTotChrgEgy_Wh:0, ChrMgmt_BattChrgCnt_Tms:0], variable=tec_ChrgEgyCalInfo}
      nv-require-com-spec{init-value=fields=[ChrMgmt_OBCSideTotDchaEgy_Wh:0, ChrMgmt_PODSideTotChrgEgy_Wh:0, ChrMgmt_BattSideTotChrgEgy_Wh:0, ChrMgmt_DCChrgrSideTotChrgEgy_Wh:0, ChrMgmt_OBCSideTotChrgEgy_Wh:0, ChrMgmt_BattChrgCnt_Tms:0], variable=tec_ChrgEgyCalInfo}
      provided-required-interface=IF_ChrgEgyCalInfo
    require port UDS_PwrCutRequest: nonqueued-receiver-com-spec{data-element=PwrCutRequest, filter=data-filter-type=ALWAYS, init-value=0}, required-interface=UDS_PwrCutRequest
    require port RTE_R_DiagApp_DisableDCMReqInfo: nonqueued-receiver-com-spec{data-element=tec_DiagApp_DisableDCMReqInfo, filter=data-filter-type=ALWAYS, init-value=0}, required-interface=IF_DiagApp_DisableDCMReqInfo
    provide port RTE_P_ChrMgmt_PosRlyReqSts_Enum: nonqueued-sender-com-spec{data-element=tec_ChrMgmt_PosRlyReqSts_Enum, init-value=0}, provided-interface=IF_ChrMgmt_PosRlyReqSts_Enum
    provide port RTE_P_ChrMgmt_PckPTCAllwbl_Flg: nonqueued-sender-com-spec{data-element=tec_ChrMgmt_PckPTCAllwbl_Flg, init-value=0}, provided-interface=IF_ChrMgmt_PckPTCAllwbl_Flg
    7 x require port:
      RTE_R_ComM_OBCCPPwmDuty_pct: nonqueued-receiver-com-spec{data-element=tec_ComM_OBCCPPwmDuty_pct, filter=data-filter-type=ALWAYS, init-value=0}, required-interface=IF_ComM_OBCCPPwmDuty_pct
      RTE_R_ComM_RxSts_Flg: required-interface=IF_ComM_RxSts_Flg
        required-com-specs:
          data-element=tec_ComM_RxCROSts_Flg, filter=data-filter-type=ALWAYS, init-value=0
          data-element=tec_ComM_RxCEMSts_Flg, filter=data-filter-type=ALWAYS, init-value=0
          data-element=tec_ComM_RxCHMSts_Flg, filter=data-filter-type=ALWAYS, init-value=0
          data-element=tec_ComM_RxCSTSts_Flg, filter=data-filter-type=ALWAYS, init-value=0
          data-element=tec_ComM_RxCSDSts_Flg, filter=data-filter-type=ALWAYS, init-value=0
          data-element=tec_ComM_RxCCSSts_Flg, filter=data-filter-type=ALWAYS, init-value=0
          data-element=tec_ComM_RxCMLSts_Flg, filter=data-filter-type=ALWAYS, init-value=0
          data-element=tec_ComM_RxCRMSts_Flg, filter=data-filter-type=ALWAYS, init-value=0
      RTE_R_HvMgmt_BMSNegRlyActSts_Enum: nonqueued-receiver-com-spec{data-element=tec_HvMgmt_BMSNegRlyActSts_Enum, filter=data-filter-type=ALWAYS, init-value=0}, required-interface=IF_HvMgmt_BMSNegRlyActSts_Enum
      RTE_R_DCChrMgmt_BSTTxReqSts: nonqueued-receiver-com-spec{data-element=tec_DCChrMgmt_BSTTxReqSts, filter=data-filter-type=ALWAYS, init-value=0}, required-interface=IF_DCChrMgmt_BSTTxReqSts
      RTE_R_OBCMgmt_OBCEnaCmd_Enum: nonqueued-receiver-com-spec{data-element=tec_OBCMgmt_OBCEnaCmd_Enum, filter=data-filter-type=ALWAYS, init-value=0}, required-interface=IF_OBCMgmt_OBCEnaCmd_Enum
      RTE_R_ComM_BMSBattAllowChrgIDc_A: nonqueued-receiver-com-spec{data-element=tec_ComM_BMSBattAllowChrgIDc_A, filter=data-filter-type=ALWAYS, init-value=0}, required-interface=IF_ComM_BMSBattAllowChrgIDc_A
      RTE_R_ComM_BMSPTCRlyStsInfo: nonqueued-receiver-com-spec{data-element=tec_ComM_BMSPTCRlyStsInfo, filter=data-filter-type=ALWAYS, init-value=0}, required-interface=IF_ComM_BMSPTCRlyStsInfo
    provide port RTE_P_ChrMgmt_PreheatReqHvOff: nonqueued-sender-com-spec{data-element=tec_ChrMgmt_PreheatReqHvOff, init-value=0}, provided-interface=IF_ChrMgmt_PreheatReqHvOff
    require port RTE_R_ComM_BMSBattMaxChrgnUDc_V: nonqueued-receiver-com-spec{data-element=tec_ComM_BMSBattMaxChrgnUDc_V, filter=data-filter-type=ALWAYS, init-value=0}, required-interface=IF_ComM_BMSBattMaxChrgnUDc_V
    require port RTE_R_VehMot_VehSpdVld_Flg: nonqueued-receiver-com-spec{data-element=tec_VehMot_VehSpdVld_Flg, filter=data-filter-type=ALWAYS, init-value=0}, required-interface=IF_VehMot_VehSpdVld_Flg
    4 x component:
      CtAp_ChrgStat: type=CtAp_ChrgStat
      CtAp_ChrgEgyCal: type=CtAp_ChrgEgyCal
      CtAp_ChrgSdl: type=CtAp_ChrgSdl
      CtAp_ChrgPreHeat: type=CtAp_ChrgPreHeat
    delegate CtAp_ChrgStat.RTE_R_ComM_BMSChrgCmplSts_Enum <-> outer port RTE_R_ComM_BMSChrgCmplSts_Enum
    delegate CtAp_ChrgStat.RTE_R_ComM_IVIMinDchaSOCSet_Enum <-> outer port RTE_R_ComM_IVIMinDchaSOCSet_Enum
    delegate CtAp_ChrgStat.RTE_R_ComM_OBCChrgSts_Enum <-> outer port RTE_R_ComM_OBCChrgSts_Enum
    delegate CtAp_ChrgStat.RTE_R_OBCMgmt_AcChrgnSts_Enum <-> outer port RTE_R_OBCMgmt_AcChrgnSts_Enum
    delegate CtAp_ChrgStat.RTE_P_ChgMrmt_DchaAbortRsn_Enum <-> outer port RTE_P_ChgMrmt_DchaAbortRsn_Enum
    delegate CtAp_ChrgStat.RTE_P_ChrMgmt_ChrgStsJmpDTC_Bus <-> outer port RTE_P_ChrMgmt_ChrgStsJmpDTC_Bus
    delegate CtAp_ChrgStat.RTE_P_ChrMgmt_CC2UDcDTC_Bus <-> outer port RTE_P_ChrMgmt_CC2UDcDTC_Bus
    delegate CtAp_ChrgStat.RTE_P_ChrMgmt_ChrgMemFlt_Flg <-> outer port RTE_P_ChrMgmt_ChrgMemFlt_Flg
    delegate CtAp_ChrgStat.RTE_P_ChrMgmt_DchaAbortSOC_pct <-> outer port RTE_P_ChrMgmt_DchaAbortSOC_pct
    delegate CtAp_ChrgStat.RTE_P_ChrMgmt_KeepWrm_Flg <-> outer port RTE_P_ChrMgmt_KeepWrm_Flg
    delegate CtAp_ChrgStat.RTE_P_ChrMgmt_ChrgAbortRsn_Enum <-> outer port RTE_P_ChrMgmt_ChrgAbortRsn_Enum
    delegate CtAp_ChrgStat.RTE_P_ChrMgmt_ChrgProcCmt_Enum <-> outer port RTE_P_ChrMgmt_ChrgProcCmt_Enum
    delegate CtAp_ChrgStat.RTE_P_ChrMgmt_ChrgStsJmpErr_Bus <-> outer port RTE_P_ChrMgmt_ChrgStsJmpErr_Bus
    delegate CtAp_ChrgStat.RTE_P_ChrMgmt_ChrgSts_Enum <-> outer port RTE_P_ChrMgmt_ChrgSts_Enum
    delegate CtAp_ChrgStat.RTE_P_ChrMgmt_DcChrgCmplSts_Enum <-> outer port RTE_P_ChrMgmt_DcChrgCmplSts_Enum
    delegate CtAp_ChrgStat.RTE_P_ChrMgmt_OBCCtrlMdlSts_Enum <-> outer port RTE_P_ChrMgmt_OBCCtrlMdlSts_Enum
    delegate CtAp_ChrgStat.RTE_P_ChrMgmt_PlugSts_Enum <-> outer port RTE_P_ChrMgmt_PlugSts_Enum
    delegate CtAp_ChrgStat.RTE_P_ChrMgmt_ReqLvActv_Flg <-> outer port RTE_P_ChrMgmt_ReqLvActv_Flg
    delegate CtAp_ChrgStat.RTE_P_ChrMgmt_ChrgTarSOC_pct <-> outer port RTE_P_ChrMgmt_ChrgTarSOC_pct
    delegate CtAp_ChrgStat.RTE_P_ChrMgmt_CC2UDcErr_Bus <-> outer port RTE_P_ChrMgmt_CC2UDcErr_Bus
    delegate CtAp_ChrgStat.RTE_P_ChrMgmt_DcChrgAllwd_Flg <-> outer port RTE_P_ChrMgmt_DcChrgAllwd_Flg
    delegate CtAp_ChrgStat.RTE_P_ChrMgmt_OBCEnaAllwd_Flg <-> outer port RTE_P_ChrMgmt_OBCEnaAllwd_Flg
    delegate CtAp_ChrgSdl.RTE_P_ChrMgmt_ChrgTim_min <-> outer port RTE_P_ChrMgmt_ChrgTim_min
    delegate CtAp_ChrgSdl.RTE_P_ChrMgmt_ChrgnRemnTim_min <-> outer port RTE_P_ChrMgmt_ChrgnRemnTim_min
    delegate CtAp_ChrgSdl.RTE_P_ChrMgmt_KeepWrmTim_min <-> outer port RTE_P_ChrMgmt_KeepWrmTim_min
    delegate CtAp_ChrgPreHeat.RTE_P_ChrMgmt_PreheatPODDiReq_Flg <-> outer port RTE_P_ChrMgmt_PreheatPODDiReq_Flg
    delegate CtAp_ChrgPreHeat.RTE_P_ChrMgmt_AcPreheatUDcCtrlErrDTC_Bus <-> outer port RTE_P_ChrMgmt_AcPreheatUDcCtrlErrDTC_Bus
    delegate CtAp_ChrgPreHeat.RTE_P_ChrMgmt_AcPreheatUDcCtrlErr_Bus <-> outer port RTE_P_ChrMgmt_AcPreheatUDcCtrlErr_Bus
    delegate CtAp_ChrgPreHeat.RTE_P_ChrMgmt_DcPreheatUDcCtrlErrDTC_Bus <-> outer port RTE_P_ChrMgmt_DcPreheatUDcCtrlErrDTC_Bus
    delegate CtAp_ChrgPreHeat.RTE_P_ChrMgmt_DcPreheatUDcCtrlErr_Bus <-> outer port RTE_P_ChrMgmt_DcPreheatUDcCtrlErr_Bus
    delegate CtAp_ChrgPreHeat.RTE_P_ChrMgmt_PreheatIRChkErrDTC_Bus <-> outer port RTE_P_ChrMgmt_PreheatIRChkErrDTC_Bus
    delegate CtAp_ChrgPreHeat.RTE_P_ChrMgmt_PreheatIRChkErr_Bus <-> outer port RTE_P_ChrMgmt_PreheatIRChkErr_Bus
    delegate CtAp_ChrgPreHeat.RTE_P_ChrMgmt_PreheatSts_Enum <-> outer port RTE_P_ChrMgmt_PreheatSts_Enum
    delegate CtAp_ChrgEgyCal.RTE_P_ChrMgmt_ChrgPwr_kW <-> outer port RTE_P_ChrMgmt_ChrgPwr_kW
    delegate CtAp_ChrgEgyCal.RTE_P_ChrMgmt_DcChrgrSideSngChrgEgy_kWh <-> outer port RTE_P_ChrMgmt_DcChrgrSideSngChrgEgy_kWh
    delegate CtAp_ChrgEgyCal.RTE_P_ChrMgmt_OBCSideSngDchaEgy_kWh <-> outer port RTE_P_ChrMgmt_OBCSideSngDchaEgy_kWh
    delegate CtAp_ChrgEgyCal.RTE_P_ChrMgmt_SngChrgEgy_kWh <-> outer port RTE_P_ChrMgmt_SngChrgEgy_kWh
    delegate CtAp_ChrgEgyCal.RTE_P_ChrMgmt_VCUCalcdPODIDc_A <-> outer port RTE_P_ChrMgmt_VCUCalcdPODIDc_A
    delegate CtAp_ChrgEgyCal.RTE_P_ChrMgmt_VCUCalcdPODInitIDc_A <-> outer port RTE_P_ChrMgmt_VCUCalcdPODInitIDc_A
    delegate CtAp_ChrgEgyCal.RTE_P_ChrMgmt_VCUDispChrgU_V <-> outer port RTE_P_ChrMgmt_VCUDispChrgU_V
    delegate CtAp_ChrgEgyCal.RTE_P_ChrMgmt_BattSideSngChrgEgy_kWh <-> outer port RTE_P_ChrMgmt_BattSideSngChrgEgy_kWh
    delegate CtAp_ChrgEgyCal.RTE_P_ChrMgmt_PODSideSngChrgEgy_kWh <-> outer port RTE_P_ChrMgmt_PODSideSngChrgEgy_kWh
    delegate CtAp_ChrgEgyCal.RTE_P_ChrMgmt_OBCSideSngChrgEgy_kWh <-> outer port RTE_P_ChrMgmt_OBCSideSngChrgEgy_kWh
    delegate CtAp_ChrgEgyCal.RTE_P_ChrMgmt_VCUDispChrgI_A <-> outer port RTE_P_ChrMgmt_VCUDispChrgI_A
    connect CtAp_ChrgSdl.RTE_P_ChrMgmt_KeepWrmTim_min -> CtAp_ChrgStat.RTE_R_ChrMgmt_KeepWrmTim_min
    connect CtAp_ChrgPreHeat.RTE_P_ChrMgmt_AcPreheatUDcCtrlErr_Bus -> CtAp_ChrgStat.RTE_R_ChrMgmt_AcPreheatUDcCtrlErr_Bus
    connect CtAp_ChrgPreHeat.RTE_P_ChrMgmt_DcPreheatUDcCtrlErr_Bus -> CtAp_ChrgStat.RTE_R_ChrMgmt_DcPreheatUDcCtrlErr_Bus
    delegate CtAp_ChrgStat.RTE_R_ComM_NodComFailr <-> outer port RTE_R_ComM_NodComFailr
    delegate CtAp_ChrgStat.RTE_R_ComM_OBCOutpIDc_A <-> outer port RTE_R_ComM_OBCOutpIDc_A
    delegate CtAp_ChrgStat.RTE_R_ErrMgmt_AcStop_Flg <-> outer port RTE_R_ErrMgmt_AcStop_Flg
    delegate CtAp_ChrgStat.RTE_R_ErrMgmt_DcStop_Flg <-> outer port RTE_R_ErrMgmt_DcStop_Flg
    delegate CtAp_ChrgStat.RTE_R_OBCMgmt_CPStsJmpErr_Bus <-> outer port RTE_R_OBCMgmt_CPStsJmpErr_Bus
    delegate CtAp_ChrgStat.RTE_R_OBCMgmt_OBCChrgStsErr_Bus <-> outer port RTE_R_OBCMgmt_OBCChrgStsErr_Bus
    delegate CtAp_ChrgStat.RTE_R_OBCMgmt_S2SwtClsErr_Bus <-> outer port RTE_R_OBCMgmt_S2SwtClsErr_Bus
    delegate CtAp_ChrgStat.RTE_R_ComM_CANBusOffInfo_Bus <-> outer port RTE_R_ComM_CANBusOffInfo_Bus
    delegate CtAp_ChrgStat.RTE_R_ComM_BCMAntithftSts_Enum <-> outer port RTE_R_ComM_BCMAntithftSts_Enum
    delegate CtAp_ChrgStat.RTE_R_ComM_BMSChrgSts_Enum <-> outer port RTE_R_ComM_BMSChrgSts_Enum
    delegate CtAp_ChrgStat.RTE_R_ComM_BMSKeepWrmReq_Enum <-> outer port RTE_R_ComM_BMSKeepWrmReq_Enum
    delegate CtAp_ChrgStat.RTE_R_ComM_BMSKeepWrmSts_Enum <-> outer port RTE_R_ComM_BMSKeepWrmSts_Enum
    delegate CtAp_ChrgStat.RTE_R_ComM_IVIChrgCmd_Enum <-> outer port RTE_R_ComM_IVIChrgCmd_Enum
    delegate CtAp_ChrgStat.RTE_R_ComM_ElectcLockSts_Enum <-> outer port RTE_R_ComM_ElectcLockSts_Enum
    delegate CtAp_ChrgStat.RTE_R_ComM_IVIDchaSwtSts_Enum <-> outer port RTE_R_ComM_IVIDchaSwtSts_Enum
    delegate CtAp_ChrgStat.RTE_R_ComM_IVIMaxChrgSOCSet_pct <-> outer port RTE_R_ComM_IVIMaxChrgSOCSet_pct
    delegate CtAp_ChrgStat.RTE_R_ComM_PEPSPwrMod_Enum <-> outer port RTE_R_ComM_PEPSPwrMod_Enum
    delegate CtAp_ChrgStat.RTE_R_ErrMgmt_V2LStop_Flg <-> outer port RTE_R_ErrMgmt_V2LStop_Flg
    delegate CtAp_ChrgStat.RTE_R_OBCMgmt_OBCInpUDcLoErr_Bus <-> outer port RTE_R_OBCMgmt_OBCInpUDcLoErr_Bus
    delegate CtAp_ChrgStat.RTE_R_ComM_ApptChrgMdlSts_Enum <-> outer port RTE_R_ComM_ApptChrgMdlSts_Enum
    delegate CtAp_ChrgStat.RTE_R_ErrMgmt_DcPause_Flg <-> outer port RTE_R_ErrMgmt_DcPause_Flg
    delegate CtAp_ChrgStat.RTE_R_OBCMgmt_OBCDchaStsErr_Bus <-> outer port RTE_R_OBCMgmt_OBCDchaStsErr_Bus
    delegate CtAp_ChrgStat.RTE_R_ErrMgmt_AcPause_Flg <-> outer port RTE_R_ErrMgmt_AcPause_Flg
    delegate CtAp_ChrgStat.RTE_R_HvMgmt_TCUWrkModActSts_Enum <-> outer port RTE_R_HvMgmt_TCUWrkModActSts_Enum
    delegate CtAp_ChrgStat.RTE_R_ErrMgmt_VehErrLvl_Enum <-> outer port RTE_R_ErrMgmt_VehErrLvl_Enum
    delegate CtAp_ChrgStat.RTE_R_HvMgmt_HvPwrOffReqChrgDwn_Flg <-> outer port RTE_R_HvMgmt_HvPwrOffReqChrgDwn_Flg
    delegate CtAp_ChrgStat.RTE_R_ComM_OBCCPSts_Enum <-> outer port RTE_R_ComM_OBCCPSts_Enum
    delegate CtAp_ChrgStat.RTE_R_HvMgmt_DCDCWrkModActSts_Enum <-> outer port RTE_R_HvMgmt_DCDCWrkModActSts_Enum
    delegate CtAp_ChrgStat.RTE_R_ComM_SGWChrgCmd_Enum <-> outer port RTE_R_ComM_SGWChrgCmd_Enum
    delegate CtAp_ChrgStat.RTE_R_HvMgmt_DCFCWrkModActSts_Enum <-> outer port RTE_R_HvMgmt_DCFCWrkModActSts_Enum
    delegate CtAp_ChrgStat.RTE_R_DCChrMgmt_BEMTxReqSts_Enum <-> outer port RTE_R_DCChrMgmt_BEMTxReqSts_Enum
    delegate CtAp_ChrgStat.RTE_R_ComM_OBCCCSts_Enum <-> outer port RTE_R_ComM_OBCCCSts_Enum
    delegate CtAp_ChrgStat.RTE_R_FctSftyMon_ActGear_Enum <-> outer port RTE_R_FctSftyMon_ActGear_Enum
    delegate CtAp_ChrgStat.RTE_R_ModMgmt_HvSts_Enum <-> outer port RTE_R_ModMgmt_HvSts_Enum
    delegate CtAp_ChrgStat.RTE_R_ComM_BMSBattDispSOC_pct <-> outer port RTE_R_ComM_BMSBattDispSOC_pct
    delegate CtAp_ChrgStat.RTE_R_OBCMgmt_OBCPreheatStsErr_Bus <-> outer port RTE_R_OBCMgmt_OBCPreheatStsErr_Bus
    delegate CtAp_ChrgStat.RTE_R_DCChrMgmt_DcChrgnSts_Enum <-> outer port RTE_R_DCChrMgmt_DcChrgnSts_Enum
    connect CtAp_ChrgEgyCal.RTE_P_ChrMgmt_VCUCalcdPODIDc_A -> CtAp_ChrgStat.RTE_R_ChrMgmt_VCUCalcdPODIDc_A
    connect CtAp_ChrgPreHeat.RTE_P_ChrMgmt_PreheatSts_Enum -> CtAp_ChrgStat.RTE_R_ChrMgmt_PreheatSts_Enum
    connect CtAp_ChrgPreHeat.RTE_P_ChrMgmt_PreheatIRChkErr_Bus -> CtAp_ChrgStat.RTE_R_ChrMgmt_PreheatIRChkErr_Bus
    delegate CtAp_ChrgStat.RTE_R_VehMot_VehStdl_Flg <-> outer port RTE_R_VehMot_VehStdl_Flg
    delegate CtAp_ChrgStat.RTE_R_DCChrMgmt_DcPortTempSnsrErr_Bus <-> outer port RTE_R_DCChrMgmt_DcPortTempSnsrErr_Bus
    delegate CtAp_ChrgStat.RTE_R_ComM_PODDcPosRlySts_Enum <-> outer port RTE_R_ComM_PODDcPosRlySts_Enum
    delegate CtAp_ChrgStat.RTE_R_DCChrMgmt_IRMeasEnaErr_Bus <-> outer port RTE_R_DCChrMgmt_IRMeasEnaErr_Bus
    delegate CtAp_ChrgStat.RTE_R_OBCMgmt_OBCDiErr_Bus <-> outer port RTE_R_OBCMgmt_OBCDiErr_Bus
    delegate CtAp_ChrgStat.RTE_R_LvMgmt_BSBattUDcNorm_Flg <-> outer port RTE_R_LvMgmt_BSBattUDcNorm_Flg
    delegate CtAp_ChrgStat.RTE_R_DCChrMgmt_DcPortTempErrLvl2_Bus <-> outer port RTE_R_DCChrMgmt_DcPortTempErrLvl2_Bus
    delegate CtAp_ChrgStat.RTE_P_ChrMgmt_ReqHvRdy_Flg <-> outer port RTE_P_ChrMgmt_ReqHvRdy_Flg
    delegate CtAp_ChrgStat.RTE_R_HvMgmt_BMSPosRlyActSts_Enum <-> outer port RTE_R_HvMgmt_BMSPosRlyActSts_Enum
    delegate CtAp_ChrgStat.RTE_R_IOAbs_CC2SigUDc_mV <-> outer port RTE_R_IOAbs_CC2SigUDc_mV
    delegate CtAp_ChrgStat.RTE_R_DCChrMgmt_IRMeasDiErr_Bus <-> outer port RTE_R_DCChrMgmt_IRMeasDiErr_Bus
    delegate CtAp_ChrgSdl.RTE_R_ComM_BMSRemnChrgTim_min <-> outer port RTE_R_ComM_BMSRemnChrgTim_min
    delegate CtAp_ChrgSdl.RTE_R_ComM_BattMinTemp_C <-> outer port RTE_R_ComM_BattMinTemp_C
    delegate CtAp_ChrgSdl.RTE_R_ComM_CMLMaxOutpIDc_A <-> outer port RTE_R_ComM_CMLMaxOutpIDc_A
    delegate CtAp_ChrgSdl.RTE_R_ChrMgmt_ChrgSts_Enum <-> outer port RTE_R_ChrMgmt_ChrgSts_Enum
    delegate CtAp_ChrgSdl.RTE_R_ChrMgmt_ChrgTarSOC_pct <-> outer port RTE_R_ChrMgmt_ChrgTarSOC_pct
    delegate CtAp_ChrgSdl.RTE_R_ComM_BMSBattRateCp_Ah <-> outer port RTE_R_ComM_BMSBattRateCp_Ah
    delegate CtAp_ChrgSdl.RTE_R_DCChrMgmt_DcChrgnMod_Enum <-> outer port RTE_R_DCChrMgmt_DcChrgnMod_Enum
    delegate CtAp_ChrgSdl.RTE_R_ComM_BattMaxTemp_C <-> outer port RTE_R_ComM_BattMaxTemp_C
    delegate CtAp_ChrgSdl.RTE_R_OBCMgmt_OBCOutpCpbyIDc_A <-> outer port RTE_R_OBCMgmt_OBCOutpCpbyIDc_A
    delegate CtAp_ChrgSdl.RTE_R_ComM_BMSBattDispSOC_pct <-> outer port RTE_R_ComM_BMSBattDispSOC_pct
    delegate CtAp_ChrgEgyCal.RTE_R_ComM_CCSOutpIDc_A <-> outer port RTE_R_ComM_CCSOutpIDc_A
    delegate CtAp_ChrgEgyCal.RTE_R_ComM_BMSBattIDc_A <-> outer port RTE_R_ComM_BMSBattIDc_A
    delegate CtAp_ChrgEgyCal.RTE_R_ComM_BMSBattLnkUDc_V <-> outer port RTE_R_ComM_BMSBattLnkUDc_V
    delegate CtAp_ChrgEgyCal.RTE_R_EgyMgmt_ACSysPwrCnsCalcn_Kw <-> outer port RTE_R_EgyMgmt_ACSysPwrCnsCalcn_Kw
    delegate CtAp_ChrgEgyCal.RTE_R_EgyMgmt_PackPTCPwrCnsCalcn_Kw <-> outer port RTE_R_EgyMgmt_PackPTCPwrCnsCalcn_Kw
    delegate CtAp_ChrgEgyCal.RTE_R_ComM_PODDCFCUDc_V <-> outer port RTE_R_ComM_PODDCFCUDc_V
    delegate CtAp_ChrgEgyCal.RTE_R_EgyMgmt_DCDCPwrCnsCalcn_Kw <-> outer port RTE_R_EgyMgmt_DCDCPwrCnsCalcn_Kw
    delegate CtAp_ChrgEgyCal.RTE_R_ComM_OBCOutpUDc_V <-> outer port RTE_R_ComM_OBCOutpUDc_V
    delegate CtAp_ChrgEgyCal.RTE_R_ComM_OBCOutpIDc_A <-> outer port RTE_R_ComM_OBCOutpIDc_A
    connect CtAp_ChrgStat.RTE_P_ChrMgmt_ChrgSts_Enum -> CtAp_ChrgEgyCal.RTE_R_ChrMgmt_ChrgSts_Enum
    delegate CtAp_ChrgEgyCal.RTE_R_ComM_OBCInpIAc_A <-> outer port RTE_R_ComM_OBCInpIAc_A
    delegate CtAp_ChrgEgyCal.RTE_R_ComM_CCSOutpUDc_V <-> outer port RTE_R_ComM_CCSOutpUDc_V
    delegate CtAp_ChrgEgyCal.RTE_R_ComM_BMSBattUDc_V <-> outer port RTE_R_ComM_BMSBattUDc_V
    delegate CtAp_ChrgEgyCal.RTE_R_ComM_OBCInpUAc_V <-> outer port RTE_R_ComM_OBCInpUAc_V
    delegate CtAp_ChrgEgyCal.RTE_R_ComM_AcChrgPha_Enum <-> outer port RTE_R_ComM_AcChrgPha_Enum
    delegate CtAp_ChrgPreHeat.RTE_R_ComM_BMSBattPckUDc_V <-> outer port RTE_R_ComM_BMSBattPckUDc_V
    delegate CtAp_ChrgPreHeat.RTE_R_ComM_OBCChrgSts_Enum <-> outer port RTE_R_ComM_OBCChrgSts_Enum
    delegate CtAp_ChrgPreHeat.RTE_R_ComM_OBCOutpUDc_V <-> outer port RTE_R_ComM_OBCOutpUDc_V
    delegate CtAp_ChrgPreHeat.RTE_R_ComM_PODDCFCUDc_V <-> outer port RTE_R_ComM_PODDCFCUDc_V
    delegate CtAp_ChrgPreHeat.RTE_R_OBCMgmt_AcChrgnSts_Enum <-> outer port RTE_R_OBCMgmt_AcChrgnSts_Enum
    delegate CtAp_ChrgPreHeat.RTE_R_HvMgmt_BMSPosRlyActSts_Enum <-> outer port RTE_R_HvMgmt_BMSPosRlyActSts_Enum
    delegate CtAp_ChrgPreHeat.RTE_R_HvMgmt_TCUWrkModActSts_Enum <-> outer port RTE_R_HvMgmt_TCUWrkModActSts_Enum
    connect CtAp_ChrgStat.RTE_P_ChrMgmt_ChrgSts_Enum -> CtAp_ChrgPreHeat.RTE_R_ChrMgmt_ChrgSts_Enum
    delegate CtAp_ChrgPreHeat.RTE_R_ComM_BMSBattIDc_A <-> outer port RTE_R_ComM_BMSBattIDc_A
    delegate CtAp_ChrgPreHeat.RTE_R_ModMgmt_HvSts_Enum <-> outer port RTE_R_ModMgmt_HvSts_Enum
    delegate CtAp_ChrgPreHeat.RTE_R_ComM_CANBusOffInfo_Bus <-> outer port RTE_R_ComM_CANBusOffInfo_Bus
    delegate CtAp_ChrgPreHeat.RTE_R_LvMgmt_BSBattUDcNorm_Flg <-> outer port RTE_R_LvMgmt_BSBattUDcNorm_Flg
    delegate CtAp_ChrgPreHeat.RTE_R_ComM_BMSChrgReqSts_Enum <-> outer port RTE_R_ComM_BMSChrgReqSts_Enum
    delegate CtAp_ChrgPreHeat.RTE_R_ComM_BMSChrgSts_Enum <-> outer port RTE_R_ComM_BMSChrgSts_Enum
    delegate CtAp_ChrgPreHeat.RTE_R_ComM_SysIRVal_kOhm <-> outer port RTE_R_ComM_SysIRVal_kOhm
    delegate CtAp_ChrgPreHeat.RTE_R_DCChrMgmt_DcChrgnSts_Enum <-> outer port RTE_R_DCChrMgmt_DcChrgnSts_Enum
    delegate CtAp_ChrgPreHeat.RTE_R_ErrMgmt_AcPause_Flg <-> outer port RTE_R_ErrMgmt_AcPause_Flg
    delegate CtAp_ChrgPreHeat.RTE_R_ErrMgmt_DcPause_Flg <-> outer port RTE_R_ErrMgmt_DcPause_Flg
    delegate CtAp_ChrgPreHeat.RTE_R_HvMgmt_DCDCWrkModActSts_Enum <-> outer port RTE_R_HvMgmt_DCDCWrkModActSts_Enum
    delegate CtAp_ChrgStat.RTE_RP_ChrgStatInfo <-> outer port RTE_RP_ChrgStatInfo
    delegate CtAp_ChrgEgyCal.RTE_RP_ChrgEgyCalInfo <-> outer port RTE_RP_ChrgEgyCalInfo
    delegate CtAp_ChrgStat.UDS_PwrCutRequest <-> outer port UDS_PwrCutRequest
    delegate CtAp_ChrgStat.RTE_R_DiagApp_DisableDCMReqInfo <-> outer port RTE_R_DiagApp_DisableDCMReqInfo
    delegate CtAp_ChrgPreHeat.RTE_R_DiagApp_DisableDCMReqInfo <-> outer port RTE_R_DiagApp_DisableDCMReqInfo
    delegate CtAp_ChrgPreHeat.RTE_P_ChrMgmt_PosRlyReqSts_Enum <-> outer port RTE_P_ChrMgmt_PosRlyReqSts_Enum
    delegate CtAp_ChrgPreHeat.RTE_P_ChrMgmt_PckPTCAllwbl_Flg <-> outer port RTE_P_ChrMgmt_PckPTCAllwbl_Flg
    delegate CtAp_ChrgPreHeat.RTE_R_ComM_AcChrgPha_Enum <-> outer port RTE_R_ComM_AcChrgPha_Enum
    delegate CtAp_ChrgStat.RTE_R_ComM_OBCCPPwmDuty_pct <-> outer port RTE_R_ComM_OBCCPPwmDuty_pct
    delegate CtAp_ChrgStat.RTE_R_ComM_RxSts_Flg <-> outer port RTE_R_ComM_RxSts_Flg
    delegate CtAp_ChrgStat.RTE_R_HvMgmt_BMSNegRlyActSts_Enum <-> outer port RTE_R_HvMgmt_BMSNegRlyActSts_Enum
    delegate CtAp_ChrgStat.RTE_R_DCChrMgmt_BSTTxReqSts <-> outer port RTE_R_DCChrMgmt_BSTTxReqSts
    delegate CtAp_ChrgStat.RTE_R_OBCMgmt_OBCEnaCmd_Enum <-> outer port RTE_R_OBCMgmt_OBCEnaCmd_Enum
    delegate CtAp_ChrgSdl.RTE_R_ComM_BMSBattIDc_A <-> outer port RTE_R_ComM_BMSBattIDc_A
    delegate CtAp_ChrgSdl.RTE_R_ComM_BMSBattAllowChrgIDc_A <-> outer port RTE_R_ComM_BMSBattAllowChrgIDc_A
    delegate CtAp_ChrgSdl.RTE_R_ComM_BMSBattLnkUDc_V <-> outer port RTE_R_ComM_BMSBattLnkUDc_V
    delegate CtAp_ChrgSdl.RTE_R_EgyMgmt_ACSysPwrCnsCalcn_Kw <-> outer port RTE_R_EgyMgmt_ACSysPwrCnsCalcn_Kw
    delegate CtAp_ChrgSdl.RTE_R_EgyMgmt_DCDCPwrCnsCalcn_Kw <-> outer port RTE_R_EgyMgmt_DCDCPwrCnsCalcn_Kw
    delegate CtAp_ChrgSdl.RTE_R_EgyMgmt_PackPTCPwrCnsCalcn_Kw <-> outer port RTE_R_EgyMgmt_PackPTCPwrCnsCalcn_Kw
    delegate CtAp_ChrgPreHeat.RTE_R_ComM_BMSPTCRlyStsInfo <-> outer port RTE_R_ComM_BMSPTCRlyStsInfo
    delegate CtAp_ChrgPreHeat.RTE_P_ChrMgmt_PreheatReqHvOff <-> outer port RTE_P_ChrMgmt_PreheatReqHvOff
    delegate CtAp_ChrgPreHeat.RTE_R_ComM_BMSBattMaxChrgnUDc_V <-> outer port RTE_R_ComM_BMSBattMaxChrgnUDc_V
    delegate CtAp_ChrgPreHeat.RTE_R_ComM_ElectcLockSts_Enum <-> outer port RTE_R_ComM_ElectcLockSts_Enum
    delegate CtAp_ChrgStat.RTE_R_VehMot_VehSpdVld_Flg <-> outer port RTE_R_VehMot_VehSpdVld_Flg
